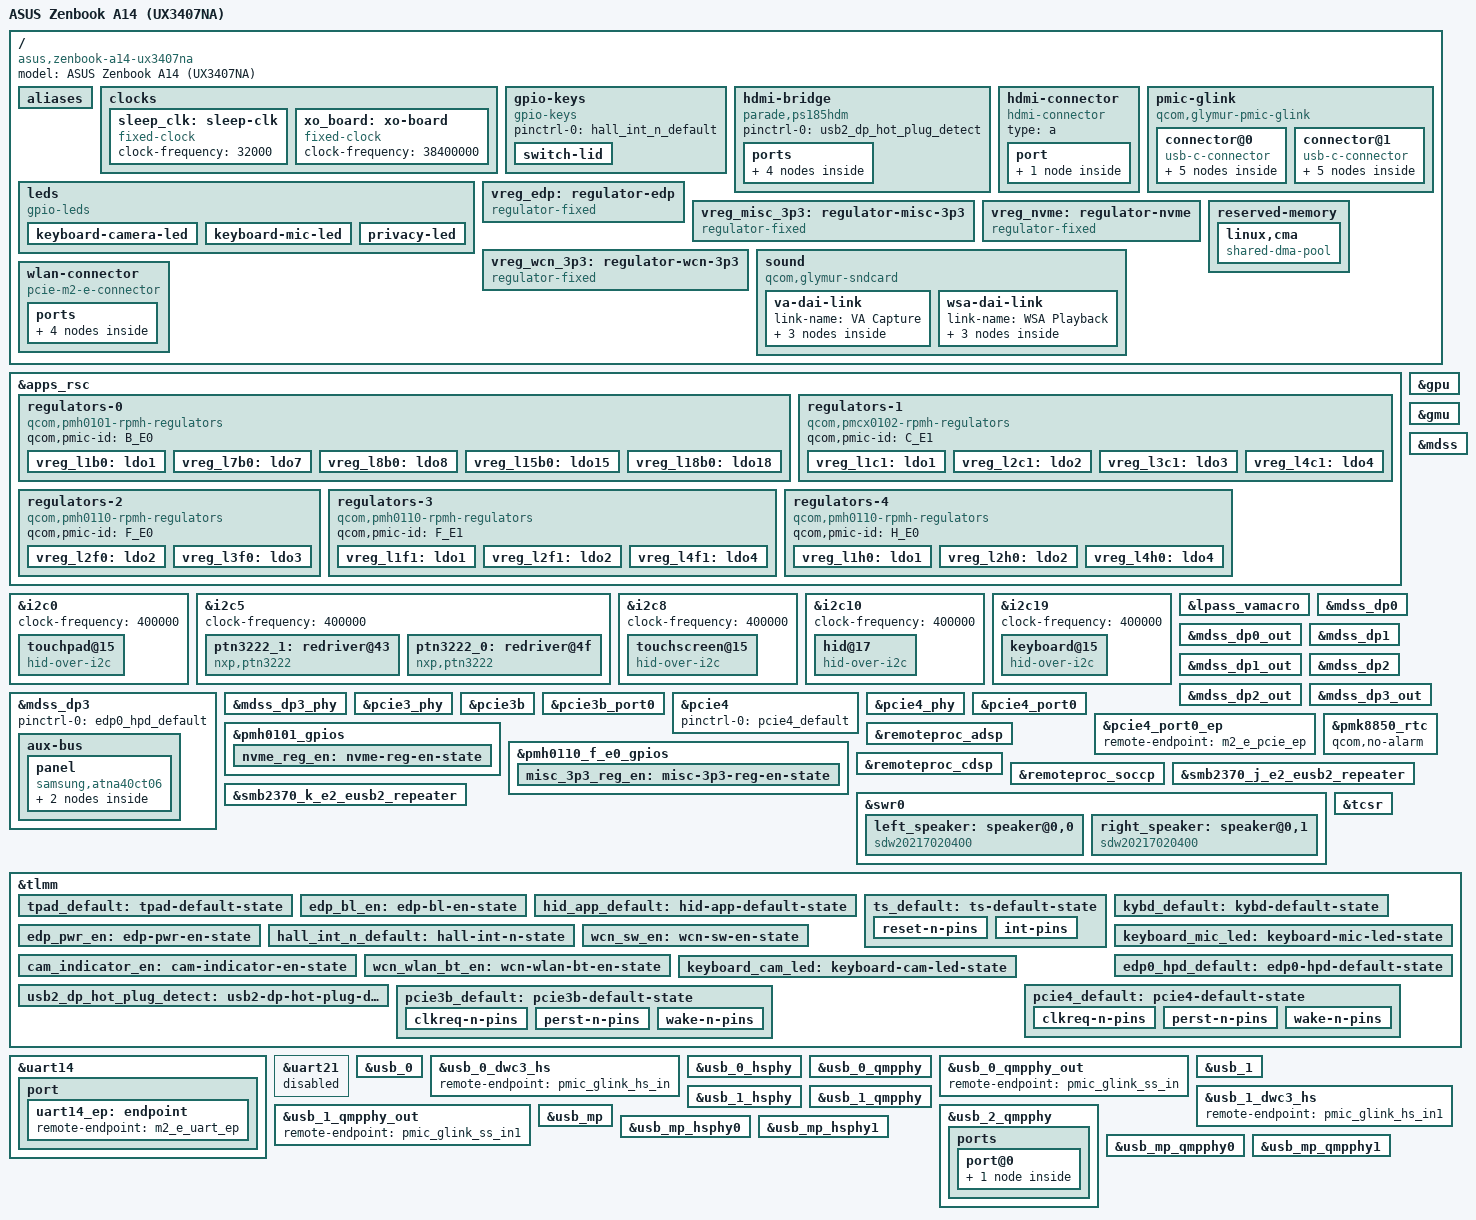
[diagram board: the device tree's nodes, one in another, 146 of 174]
// SPDX-License-Identifier: BSD-3-Clause
/*
 * Copyright (c) Qualcomm Technologies, Inc. and/or its subsidiaries.
 */
/dts-v1/;

#include "glymur.dtsi"

#include "pmcx0102.dtsi"
#include "pmh0101.dtsi"
#include "pmh0110-glymur.dtsi"
#include "pmh0104-glymur.dtsi"
#include "pmk8850.dtsi"
#include "smb2370.dtsi"

#include <dt-bindings/input/gpio-keys.h>
#include <dt-bindings/input/input.h>
#include <dt-bindings/leds/common.h>
#include <dt-bindings/pinctrl/qcom,pmic-gpio.h>

/ {
	compatible = "asus,zenbook-a14-ux3407na", "qcom,glymur";
	model = "ASUS Zenbook A14 (UX3407NA)";

	aliases {
		i2c0 = &i2c0;
		i2c5 = &i2c5;
		i2c8 = &i2c8;
		i2c10 = &i2c10;
		i2c19 = &i2c19;
		serial0 = &uart14;
	};

	clocks {
		sleep_clk: sleep-clk {
			compatible = "fixed-clock";
			clock-frequency = <32000>;
			#clock-cells = <0>;
		};

		xo_board: xo-board {
			compatible = "fixed-clock";
			clock-frequency = <38400000>;
			#clock-cells = <0>;
		};
	};

	gpio-keys {
		compatible = "gpio-keys";

		pinctrl-0 = <&hall_int_n_default>;
		pinctrl-names = "default";

		switch-lid {
			label = "lid";
			gpios = <&tlmm 92 GPIO_ACTIVE_LOW>;
			linux,input-type = <EV_SW>;
			linux,code = <SW_LID>;
			wakeup-source;
			wakeup-event-action = <EV_ACT_DEASSERTED>;
		};
	};

	hdmi-bridge {
		compatible = "parade,ps185hdm";

		pinctrl-0 = <&usb2_dp_hot_plug_detect>;
		pinctrl-names = "default";

		ports {
			#address-cells = <1>;
			#size-cells = <0>;

			port@0 {
				reg = <0>;

				hdmi_bridge_in: endpoint {
					remote-endpoint = <&usb_2_qmpphy_out_dp>;
				};
			};

			port@1 {
				reg = <1>;

				hdmi_bridge_out: endpoint {
					remote-endpoint = <&hdmi_con>;
				};
			};
		};
	};

	hdmi-connector {
		compatible = "hdmi-connector";
		type = "a";

		port {
			hdmi_con: endpoint {
				remote-endpoint = <&hdmi_bridge_out>;
			};
		};
	};

	leds {
		compatible = "gpio-leds";

		pinctrl-0 = <&cam_indicator_en>,
			    <&keyboard_cam_led>,
			    <&keyboard_mic_led>;
		pinctrl-names = "default";

		keyboard-camera-led {
			function = LED_FUNCTION_INDICATOR;
			color = <LED_COLOR_ID_ORANGE>;
			gpios = <&tlmm 120 GPIO_ACTIVE_HIGH>;
			default-state = "off";
			panic-indicator;
		};

		keyboard-mic-led {
			function = LED_FUNCTION_MICMUTE;
			color = <LED_COLOR_ID_ORANGE>;
			gpios = <&tlmm 98 GPIO_ACTIVE_LOW>;
			default-state = "off";
			panic-indicator;
		};

		privacy-led {
			function = LED_FUNCTION_INDICATOR;
			color = <LED_COLOR_ID_WHITE>;
			gpios = <&tlmm 111 GPIO_ACTIVE_HIGH>;
			default-state = "off";
			panic-indicator;
		};
	};

	pmic-glink {
		compatible = "qcom,glymur-pmic-glink",
			     "qcom,pmic-glink";
		#address-cells = <1>;
		#size-cells = <0>;

		/* Left side display-adjacent port */
		connector@0 {
			compatible = "usb-c-connector";
			reg = <0>;
			power-role = "dual";
			data-role = "dual";

			ports {
				#address-cells = <1>;
				#size-cells = <0>;

				port@0 {
					reg = <0>;

					pmic_glink_hs_in: endpoint {
						remote-endpoint = <&usb_0_dwc3_hs>;
					};
				};

				port@1 {
					reg = <1>;

					pmic_glink_ss_in: endpoint {
						remote-endpoint = <&usb_0_qmpphy_out>;
					};
				};
			};
		};

		/* Left side user-adjacent port */
		connector@1 {
			compatible = "usb-c-connector";
			reg = <1>;
			power-role = "dual";
			data-role = "dual";

			ports {
				#address-cells = <1>;
				#size-cells = <0>;

				port@0 {
					reg = <0>;

					pmic_glink_hs_in1: endpoint {
						remote-endpoint = <&usb_1_dwc3_hs>;
					};
				};

				port@1 {
					reg = <1>;

					pmic_glink_ss_in1: endpoint {
						remote-endpoint = <&usb_1_qmpphy_out>;
					};
				};
			};
		};
	};

	vreg_edp: regulator-edp {
		compatible = "regulator-fixed";

		regulator-name = "VREG_EDP_3P3";
		regulator-min-microvolt = <3300000>;
		regulator-max-microvolt = <3300000>;

		gpio = <&tlmm 70 GPIO_ACTIVE_HIGH>;
		enable-active-high;

		pinctrl-0 = <&edp_pwr_en>;
		pinctrl-names = "default";

		regulator-boot-on;
	};

	vreg_misc_3p3: regulator-misc-3p3 {
		compatible = "regulator-fixed";

		regulator-name = "VREG_MISC_3P3";
		regulator-min-microvolt = <3300000>;
		regulator-max-microvolt = <3300000>;

		gpio = <&pmh0110_f_e0_gpios 6 GPIO_ACTIVE_HIGH>;
		enable-active-high;

		pinctrl-0 = <&misc_3p3_reg_en>;
		pinctrl-names = "default";

		regulator-always-on;
		regulator-boot-on;
	};

	vreg_nvme: regulator-nvme {
		compatible = "regulator-fixed";

		regulator-name = "VREG_NVME_3P3";
		regulator-min-microvolt = <3300000>;
		regulator-max-microvolt = <3300000>;

		gpio = <&pmh0101_gpios 14 GPIO_ACTIVE_HIGH>;
		enable-active-high;

		pinctrl-0 = <&nvme_reg_en>;
		pinctrl-names = "default";

		regulator-boot-on;
	};

	vreg_wcn_3p3: regulator-wcn-3p3 {
		compatible = "regulator-fixed";

		regulator-name = "VREG_WCN_3P3";
		regulator-min-microvolt = <3300000>;
		regulator-max-microvolt = <3300000>;

		gpio = <&tlmm 94 GPIO_ACTIVE_HIGH>;
		enable-active-high;

		pinctrl-0 = <&wcn_sw_en>;
		pinctrl-names = "default";

		regulator-boot-on;
	};

	reserved-memory {
		linux,cma {
			compatible = "shared-dma-pool";
			size = <0x0 0x10000000>;
			reusable;
			linux,cma-default;
		};
	};

	sound {
		compatible = "qcom,glymur-sndcard";
		model = "GLYMUR-ASUS-Zenbook-A14-UX3407NA";

		audio-routing = "SpkrLeft IN", "WSA WSA_SPK1 OUT",
				"SpkrRight IN", "WSA WSA_SPK2 OUT",
				"VA DMIC0", "vdd-micb",
				"VA DMIC1", "vdd-micb";

		va-dai-link {
			link-name = "VA Capture";

			codec {
				sound-dai = <&lpass_vamacro 0>;
			};

			cpu {
				sound-dai = <&q6apmbedai VA_CODEC_DMA_TX_0>;
			};

			platform {
				sound-dai = <&q6apm>;
			};
		};

		wsa-dai-link {
			link-name = "WSA Playback";

			codec {
				sound-dai = <&left_speaker>, <&right_speaker>,
					    <&swr0 0>, <&lpass_wsamacro 0>;
			};

			cpu {
				sound-dai = <&q6apmbedai WSA_CODEC_DMA_RX_0>;
			};

			platform {
				sound-dai = <&q6apm>;
			};
		};
	};

	wlan-connector {
		compatible = "pcie-m2-e-connector";
		vpcie3v3-supply = <&vreg_wcn_3p3>;
		vpcie1v8-supply = <&vreg_l15b0>;

		w-disable1-gpios = <&tlmm 117 GPIO_ACTIVE_LOW>;
		w-disable2-gpios = <&tlmm 116 GPIO_ACTIVE_LOW>;

		pinctrl-0 = <&wcn_wlan_bt_en>;
		pinctrl-names = "default";

		ports {
			#address-cells = <1>;
			#size-cells = <0>;

			port@0 {
				reg = <0>;
				#address-cells = <1>;
				#size-cells = <0>;

				m2_e_pcie_ep: endpoint@0 {
					reg = <0>;
					remote-endpoint = <&pcie4_port0_ep>;
				};
			};

			port@3 {
				reg = <3>;
				#address-cells = <1>;
				#size-cells = <0>;

				m2_e_uart_ep: endpoint@0 {
					reg = <0>;
					remote-endpoint = <&uart14_ep>;
				};
			};
		};
	};
};

&apps_rsc {
	regulators-0 {
		compatible = "qcom,pmh0101-rpmh-regulators";
		qcom,pmic-id = "B_E0";

		vreg_l1b0: ldo1 {
			regulator-name = "vreg_l1b0";
			regulator-min-microvolt = <1800000>;
			regulator-max-microvolt = <1800000>;
			regulator-initial-mode = <RPMH_REGULATOR_MODE_HPM>;
		};

		vreg_l7b0: ldo7 {
			regulator-name = "vreg_l7b0";
			regulator-min-microvolt = <3072000>;
			regulator-max-microvolt = <3072000>;
			regulator-initial-mode = <RPMH_REGULATOR_MODE_HPM>;
		};

		vreg_l8b0: ldo8 {
			regulator-name = "vreg_l8b0";
			regulator-min-microvolt = <3304000>;
			regulator-max-microvolt = <3304000>;
			regulator-initial-mode = <RPMH_REGULATOR_MODE_HPM>;
		};

		vreg_l15b0: ldo15 {
			regulator-name = "vreg_l15b0";
			regulator-min-microvolt = <1800000>;
			regulator-max-microvolt = <1800000>;
			regulator-initial-mode = <RPMH_REGULATOR_MODE_HPM>;
			/* Provides reference voltage for many undescribed components */
			regulator-always-on;
		};

		vreg_l18b0: ldo18 {
			regulator-name = "vreg_l18b0";
			regulator-min-microvolt = <1200000>;
			regulator-max-microvolt = <1200000>;
			regulator-initial-mode = <RPMH_REGULATOR_MODE_HPM>;

			/*
			 * This is also reference voltage for &pcie3b wake and
			 * reset signals.
			 */
			regulator-always-on;
		};
	};

	regulators-1 {
		compatible = "qcom,pmcx0102-rpmh-regulators";
		qcom,pmic-id = "C_E1";

		vreg_l1c1: ldo1 {
			regulator-name = "vreg_l1c1";
			regulator-min-microvolt = <912000>;
			regulator-max-microvolt = <912000>;
			regulator-initial-mode = <RPMH_REGULATOR_MODE_HPM>;
		};

		vreg_l2c1: ldo2 {
			regulator-name = "vreg_l2c1";
			regulator-min-microvolt = <1200000>;
			regulator-max-microvolt = <1200000>;
			regulator-initial-mode = <RPMH_REGULATOR_MODE_HPM>;
		};

		vreg_l3c1: ldo3 {
			regulator-name = "vreg_l3c1";
			regulator-min-microvolt = <936000>;
			regulator-max-microvolt = <936000>;
			regulator-initial-mode = <RPMH_REGULATOR_MODE_HPM>;
		};

		vreg_l4c1: ldo4 {
			regulator-name = "vreg_l4c1";
			regulator-min-microvolt = <912000>;
			regulator-max-microvolt = <912000>;
			regulator-initial-mode = <RPMH_REGULATOR_MODE_HPM>;
		};
	};

	regulators-2 {
		compatible = "qcom,pmh0110-rpmh-regulators";
		qcom,pmic-id = "F_E0";

		vreg_l2f0: ldo2 {
			regulator-name = "vreg_l2f0";
			regulator-min-microvolt = <936000>;
			regulator-max-microvolt = <936000>;
			regulator-initial-mode = <RPMH_REGULATOR_MODE_HPM>;
		};

		vreg_l3f0: ldo3 {
			regulator-name = "vreg_l3f0";
			regulator-min-microvolt = <912000>;
			regulator-max-microvolt = <912000>;
			regulator-initial-mode = <RPMH_REGULATOR_MODE_HPM>;
		};
	};

	regulators-3 {
		compatible = "qcom,pmh0110-rpmh-regulators";
		qcom,pmic-id = "F_E1";

		vreg_l1f1: ldo1 {
			regulator-name = "vreg_l1f1";
			regulator-min-microvolt = <904000>;
			regulator-max-microvolt = <904000>;
			regulator-initial-mode = <RPMH_REGULATOR_MODE_HPM>;
		};

		vreg_l2f1: ldo2 {
			regulator-name = "vreg_l2f1";
			regulator-min-microvolt = <880000>;
			regulator-max-microvolt = <880000>;
			regulator-initial-mode = <RPMH_REGULATOR_MODE_HPM>;
		};

		vreg_l4f1: ldo4 {
			regulator-name = "vreg_l4f1";
			regulator-min-microvolt = <1200000>;
			regulator-max-microvolt = <1200000>;
			regulator-initial-mode = <RPMH_REGULATOR_MODE_HPM>;
		};
	};

	regulators-4 {
		compatible = "qcom,pmh0110-rpmh-regulators";
		qcom,pmic-id = "H_E0";

		vreg_l1h0: ldo1 {
			regulator-name = "vreg_l1h0";
			regulator-min-microvolt = <936000>;
			regulator-max-microvolt = <936000>;
			regulator-initial-mode = <RPMH_REGULATOR_MODE_HPM>;
		};

		vreg_l2h0: ldo2 {
			regulator-name = "vreg_l2h0";
			regulator-min-microvolt = <880000>;
			regulator-max-microvolt = <880000>;
			regulator-initial-mode = <RPMH_REGULATOR_MODE_HPM>;
		};

		vreg_l4h0: ldo4 {
			regulator-name = "vreg_l4h0";
			regulator-min-microvolt = <1200000>;
			regulator-max-microvolt = <1200000>;
			regulator-initial-mode = <RPMH_REGULATOR_MODE_HPM>;
		};
	};
};

&gpu {
	status = "okay";
};

&gmu {
	status = "okay";
};

&i2c0 {
	clock-frequency = <400000>;

	status = "okay";

	touchpad@15 {
		compatible = "hid-over-i2c";
		reg = <0x15>;

		hid-descr-addr = <0x1>;
		interrupts-extended = <&tlmm 3 IRQ_TYPE_LEVEL_LOW>;

		vdd-supply = <&vreg_misc_3p3>;
		vddl-supply = <&vreg_l15b0>;

		pinctrl-0 = <&tpad_default>;
		pinctrl-names = "default";

		wakeup-source;
	};
};

&i2c5 {
	clock-frequency = <400000>;

	status = "okay";

	ptn3222_1: redriver@43 {
		compatible = "nxp,ptn3222";
		reg = <0x43>;

		reset-gpios = <&tlmm 184 GPIO_ACTIVE_LOW>;

		vdd3v3-supply = <&vreg_l8b0>;
		vdd1v8-supply = <&vreg_l15b0>;

		#phy-cells = <0>;
	};

	ptn3222_0: redriver@4f {
		compatible = "nxp,ptn3222";
		reg = <0x4f>;

		reset-gpios = <&tlmm 8 GPIO_ACTIVE_LOW>;

		vdd3v3-supply = <&vreg_l8b0>;
		vdd1v8-supply = <&vreg_l15b0>;

		#phy-cells = <0>;
	};
};

&i2c8 {
	clock-frequency = <400000>;

	status = "okay";

	touchscreen@15 {
		compatible = "hid-over-i2c";
		reg = <0x15>;

		hid-descr-addr = <0x1>;
		interrupts-extended = <&tlmm 51 IRQ_TYPE_LEVEL_LOW>;

		pinctrl-0 = <&ts_default>;
		pinctrl-names = "default";

		wakeup-source;
	};
};

&i2c10 {
	clock-frequency = <400000>;

	status = "okay";

	hid@17 {
		compatible = "hid-over-i2c";
		reg = <0x17>;
		interrupts-extended = <&tlmm 43 IRQ_TYPE_LEVEL_LOW>;
		hid-descr-addr = <0x1>;
		wakeup-source;

		pinctrl-0 = <&hid_app_default>;
		pinctrl-names = "default";
	};
};

&i2c19 {
	clock-frequency = <400000>;

	status = "okay";

	keyboard@15 {
		compatible = "hid-over-i2c";
		reg = <0x15>;

		hid-descr-addr = <0x1>;
		interrupts-extended = <&tlmm 67 IRQ_TYPE_LEVEL_LOW>;

		wakeup-source;

		pinctrl-0 = <&kybd_default>;
		pinctrl-names = "default";
	};
};

&lpass_vamacro {
	vdd-micb-supply = <&vreg_l1b0>;

	pinctrl-0 = <&dmic01_default>;
	pinctrl-names = "default";

	qcom,dmic-sample-rate = <2400000>;
};

&mdss {
	status = "okay";
};

&mdss_dp0 {
	status = "okay";
};

&mdss_dp0_out {
	link-frequencies = /bits/ 64 <1620000000 2700000000 5400000000 8100000000>;
};

&mdss_dp1 {
	status = "okay";
};

&mdss_dp1_out {
	link-frequencies = /bits/ 64 <1620000000 2700000000 5400000000 8100000000>;
};

&mdss_dp2 {
	status = "okay";
};

&mdss_dp2_out {
	link-frequencies = /bits/ 64 <1620000000 2700000000 5400000000 8100000000>;
};

&mdss_dp3 {
	/delete-property/ #sound-dai-cells;

	pinctrl-0 = <&edp0_hpd_default>;
	pinctrl-names = "default";

	status = "okay";

	aux-bus {
		panel {
			compatible = "samsung,atna40ct06", "samsung,atna33xc20";
			enable-gpios = <&tlmm 18 GPIO_ACTIVE_HIGH>;
			power-supply = <&vreg_edp>;

			pinctrl-0 = <&edp_bl_en>;
			pinctrl-names = "default";

			port {
				edp_panel_in: endpoint {
					remote-endpoint = <&mdss_dp3_out>;
				};
			};
		};
	};
};

&mdss_dp3_out {
	data-lanes = <0 1 2 3>;
	link-frequencies = /bits/ 64 <1620000000 2700000000 5400000000 8100000000>;

	remote-endpoint = <&edp_panel_in>;
};

&mdss_dp3_phy {
	vdda-phy-supply = <&vreg_l2f1>;
	vdda-pll-supply = <&vreg_l4f1>;

	status = "okay";
};

&pcie3_phy {
	vdda-phy-supply = <&vreg_l3c1>;
	vdda-pll-supply = <&vreg_l2c1>;

	vdda-refgen0p9-supply = <&vreg_l1c1>;
	vdda-refgen1p2-supply = <&vreg_l4f1>;

	status = "okay";
};

&pcie3b {
	vddpe-3v3-supply = <&vreg_nvme>;

	pinctrl-0 = <&pcie3b_default>;
	pinctrl-names = "default";

	status = "okay";
};

&pcie3b_port0 {
	reset-gpios = <&tlmm 155 GPIO_ACTIVE_LOW>;
	wake-gpios = <&tlmm 157 GPIO_ACTIVE_LOW>;
};

&pcie4 {
	pinctrl-0 = <&pcie4_default>;
	pinctrl-names = "default";

	status = "okay";
};

&pcie4_phy {
	vdda-phy-supply = <&vreg_l1c1>;
	vdda-pll-supply = <&vreg_l4f1>;

	status = "okay";
};

&pcie4_port0 {
	reset-gpios = <&tlmm 146 GPIO_ACTIVE_LOW>;
	wake-gpios = <&tlmm 148 GPIO_ACTIVE_LOW>;
};

&pcie4_port0_ep {
	remote-endpoint = <&m2_e_pcie_ep>;
};

&pmh0101_gpios {
	nvme_reg_en: nvme-reg-en-state {
		pins = "gpio14";
		function = "normal";
		bias-disable;
	};
};

&pmh0110_f_e0_gpios {
	misc_3p3_reg_en: misc-3p3-reg-en-state {
		pins = "gpio6";
		function = "normal";
		bias-disable;
		input-disable;
		output-enable;
		drive-push-pull;
		power-source = <1>; /* 1.8 V */
		qcom,drive-strength = <PMIC_GPIO_STRENGTH_LOW>;
	};
};

&pmk8850_rtc {
	qcom,no-alarm;
};

&remoteproc_adsp {
	firmware-name = "qcom/glymur/ASUSTeK/UX3407NA/qcadsp8480.mbn",
			"qcom/glymur/ASUSTeK/UX3407NA/adsp_dtbs.elf";

	status = "okay";
};

&remoteproc_cdsp {
	firmware-name = "qcom/glymur/ASUSTeK/UX3407NA/qccdsp8480.mbn",
			"qcom/glymur/ASUSTeK/UX3407NA/cdsp_dtbs.elf";

	status = "okay";
};

&remoteproc_soccp {
	status = "okay";
};

&smb2370_j_e2_eusb2_repeater {
	vdd18-supply = <&vreg_l15b0>;
	vdd3-supply = <&vreg_l7b0>;
};

&smb2370_k_e2_eusb2_repeater {
	vdd18-supply = <&vreg_l15b0>;
	vdd3-supply = <&vreg_l7b0>;
};

&swr0 {
	status = "okay";

	/* WSA8845, left */
	left_speaker: speaker@0,0 {
		compatible = "sdw20217020400";
		reg = <0 0>;
		reset-gpios = <&lpass_tlmm 12 GPIO_ACTIVE_LOW>;
		#sound-dai-cells = <0>;
		sound-name-prefix = "SpkrLeft";
		vdd-1p8-supply = <&vreg_l15b0>;
		vdd-io-supply = <&vreg_l18b0>;
		qcom,port-mapping = <1 2 3 7 12 14>;
	};

	/* WSA8845, right */
	right_speaker: speaker@0,1 {
		compatible = "sdw20217020400";
		reg = <0 1>;
		reset-gpios = <&lpass_tlmm 12 GPIO_ACTIVE_LOW>;
		#sound-dai-cells = <0>;
		sound-name-prefix = "SpkrRight";
		vdd-1p8-supply = <&vreg_l15b0>;
		vdd-io-supply = <&vreg_l18b0>;
		qcom,port-mapping = <4 5 6 7 13 15>;
	};
};

&tcsr {
	vdda-qrefrpt0-0p9-supply = <&vreg_l2f1>;
	vdda-qrefrpt1-0p9-supply = <&vreg_l2f1>;
	vdda-qrefrpt2-0p9-supply = <&vreg_l2f1>;
	vdda-qrefrpt3-0p9-supply = <&vreg_l2h0>;
	vdda-qrefrpt4-0p9-supply = <&vreg_l2h0>;
	vdda-qrefrx0-0p9-supply = <&vreg_l2f1>;
	vdda-qrefrx1-0p9-supply = <&vreg_l2f1>;
	vdda-qrefrx2-0p9-supply = <&vreg_l2f1>;
	vdda-qrefrx4-0p9-supply = <&vreg_l2h0>;
	vdda-qrefrx5-0p9-supply = <&vreg_l3f0>;
	vdda-qreftx0-0p9-supply = <&vreg_l3f0>;
	vdda-qreftx0-1p2-supply = <&vreg_l4h0>;
	vdda-qreftx1-0p9-supply = <&vreg_l1f1>;
	vdda-refgen3-0p9-supply = <&vreg_l2f0>;
	vdda-refgen3-1p2-supply = <&vreg_l4h0>;
	vdda-refgen4-0p9-supply = <&vreg_l1f1>;
	vdda-refgen4-1p2-supply = <&vreg_l4f1>;
};

&tlmm {
	gpio-reserved-ranges = <4 4>, /* EC Secure */
			       <10 2>, /* OOB UART */
			       <44 4>, /* TPM */
			       <65 1>, /* EC reset */
			       <90 2>; /* TPM */

	tpad_default: tpad-default-state {
		pins = "gpio3";
		function = "gpio";
		bias-disable;
	};

	edp_bl_en: edp-bl-en-state {
		pins = "gpio18";
		function = "gpio";
		drive-strength = <16>;
		bias-disable;
	};

	hid_app_default: hid-app-default-state {
		pins = "gpio43";
		function = "gpio";
		bias-disable;
	};

	ts_default: ts-default-state {
		reset-n-pins {
			pins = "gpio48";
			function = "gpio";
			bias-disable;
		};

		int-pins {
			pins = "gpio51";
			function = "gpio";
			bias-disable;
		};
	};

	kybd_default: kybd-default-state {
		pins = "gpio67";
		function = "gpio";
		bias-disable;
	};

	edp_pwr_en: edp-pwr-en-state {
		pins = "gpio70";
		function = "gpio";
		drive-strength = <16>;
		bias-disable;
	};

	hall_int_n_default: hall-int-n-state {
		pins = "gpio92";
		function = "gpio";
		bias-disable;
	};

	wcn_sw_en: wcn-sw-en-state {
		pins = "gpio94";
		function = "gpio";
		drive-strength = <2>;
		bias-disable;
	};

	keyboard_mic_led: keyboard-mic-led-state {
		pins = "gpio98";
		function = "gpio";
		drive-strength = <2>;
		bias-disable;
	};

	cam_indicator_en: cam-indicator-en-state {
		pins = "gpio111";
		function = "gpio";
		drive-strength = <2>;
		bias-disable;
	};

	wcn_wlan_bt_en: wcn-wlan-bt-en-state {
		pins = "gpio116", "gpio117";
		function = "gpio";
		drive-strength = <2>;
		bias-disable;
	};

	edp0_hpd_default: edp0-hpd-default-state {
		pins = "gpio119";
		function = "edp0_hot";
		bias-disable;
	};

	keyboard_cam_led: keyboard-cam-led-state {
		pins = "gpio120";
		function = "gpio";
		drive-strength = <2>;
		bias-disable;
	};

	usb2_dp_hot_plug_detect: usb2-dp-hot-plug-detect-state {
		pins = "gpio126";
		function = "usb2_dp";
		bias-disable;
	};

	pcie4_default: pcie4-default-state {
		clkreq-n-pins {
			pins = "gpio147";
			function = "pcie4_clk_req_n";
			drive-strength = <2>;
			bias-pull-up;
		};

		perst-n-pins {
			pins = "gpio146";
			function = "gpio";
			drive-strength = <2>;
			bias-disable;
		};

		wake-n-pins {
			pins = "gpio148";
			function = "gpio";
			drive-strength = <2>;
			bias-pull-up;
		};
	};

	pcie3b_default: pcie3b-default-state {
		clkreq-n-pins {
			pins = "gpio156";
			function = "pcie3b_clk";
			drive-strength = <2>;
			bias-pull-up;
		};

		perst-n-pins {
			pins = "gpio155";
			function = "gpio";
			drive-strength = <2>;
			bias-disable;
		};

		wake-n-pins {
			pins = "gpio157";
			function = "gpio";
			drive-strength = <2>;
			bias-pull-up;
		};
	};
};

&uart14 {
	status = "okay";

	port {
		uart14_ep: endpoint {
			remote-endpoint = <&m2_e_uart_ep>;
		};
	};
};

&uart21 {
	status = "disabled";
};

&usb_0 {
	status = "okay";
};

&usb_0_dwc3_hs {
	remote-endpoint = <&pmic_glink_hs_in>;
};

&usb_0_hsphy {
	vdd-supply = <&vreg_l3f0>;
	vdda12-supply = <&vreg_l4h0>;

	phys = <&smb2370_j_e2_eusb2_repeater>;

	status = "okay";
};

&usb_0_qmpphy {
	vdda-phy-supply = <&vreg_l3f0>;
	vdda-pll-supply = <&vreg_l4h0>;
	refgen-supply = <&vreg_l2f0>;

	status = "okay";
};

&usb_0_qmpphy_out {
	remote-endpoint = <&pmic_glink_ss_in>;
};

&usb_1 {
	status = "okay";
};

&usb_1_dwc3_hs {
	remote-endpoint = <&pmic_glink_hs_in1>;
};

&usb_1_hsphy {
	vdd-supply = <&vreg_l3f0>;
	vdda12-supply = <&vreg_l4h0>;

	phys = <&smb2370_k_e2_eusb2_repeater>;

	status = "okay";
};

&usb_1_qmpphy {
	vdda-phy-supply = <&vreg_l1h0>;
	vdda-pll-supply = <&vreg_l4h0>;
	refgen-supply = <&vreg_l2f0>;

	status = "okay";
};

&usb_1_qmpphy_out {
	remote-endpoint = <&pmic_glink_ss_in1>;
};

&usb_2_qmpphy {
	vdda-phy-supply = <&vreg_l4c1>;
	vdda-pll-supply = <&vreg_l4f1>;
	refgen-supply = <&vreg_l4f1>;

	/delete-property/ mode-switch;
	/delete-property/ orientation-switch;

	status = "okay";

	ports {
		port@0 {
			#address-cells = <1>;
			#size-cells = <0>;

			/delete-node/ endpoint;

			usb_2_qmpphy_out_dp: endpoint@0 {
				reg = <0>;

				data-lanes = <3 2 1 0>;
				remote-endpoint = <&hdmi_bridge_in>;
			};
		};
	};
};

&usb_mp {
	status = "okay";
};

&usb_mp_hsphy0 {
	vdd-supply = <&vreg_l2h0>;
	vdda12-supply = <&vreg_l4h0>;

	phys = <&ptn3222_0>;

	status = "okay";
};

&usb_mp_hsphy1 {
	vdd-supply = <&vreg_l2h0>;
	vdda12-supply = <&vreg_l4h0>;

	phys = <&ptn3222_1>;

	status = "okay";
};

&usb_mp_qmpphy0 {
	vdda-phy-supply = <&vreg_l2h0>;
	vdda-pll-supply = <&vreg_l4h0>;
	refgen-supply = <&vreg_l4f1>;

	status = "okay";
};

&usb_mp_qmpphy1 {
	vdda-phy-supply = <&vreg_l2h0>;
	vdda-pll-supply = <&vreg_l4h0>;
	refgen-supply = <&vreg_l4f1>;

	status = "okay";
};
